AUTOSAR XML (schema 00045)
package /SpiSync
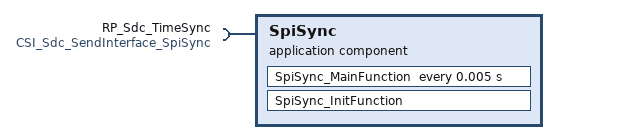
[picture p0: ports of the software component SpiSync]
  application sw component type SpiSync
    require port RP_Sdc_TimeSync: required-interface=CSI_Sdc_SendInterface_SpiSync
    behavior SpiSync_IB: handle-termination-and-restart=NO-SUPPORT
      init event InitEvt_SpiSync_InitFunction: start-on-event=SpiSync_InitFunction
      timing event TimingEvt_SpiSync_MainFunction: start-on-event=SpiSync_MainFunction, period=0.005
      runnable SpiSync_InitFunction
      runnable SpiSync_MainFunction
        sync call scp_Time: operation=RP_Sdc_TimeSync.TimeSyncMsg, timeout=0.0
        sync call scp_UTC: operation=RP_Sdc_TimeSync.TimeSyncUtc, timeout=0.0
  swc implementation SpiSyncImpl: programming-language=C, sw-version=0.0.1, vendor-id=0, behavior=SpiSync_IB
    code-descriptors:
      code CodeGen: artifact-descriptors=[{short-label=SWSRC, category=SWSRC}, {short-label=SWHDR, category=SWHDR}]
    resource consumption Resource
      memory section CODE: sw-addrmethod=CODE
      memory section VAR_UNSPECIFIED: sw-addrmethod=VAR
